# CH585SFR register map
Vendor: WCH Ltd.; Series: CH58x; File version: 1.0
CPU: RISC-V r0p0, little endian, no MPU, no FPU, 2 interrupt priority bits
Registers are 8-bit, Read or Write, reset 0x0 unless marked. A register's access mark holds for its fields unless they carry their own. Offsets are from the block's base; [hi:lo] are bit positions.

## TouchKey — Touch buttons
Base 0x40001000
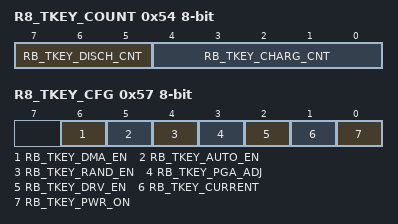
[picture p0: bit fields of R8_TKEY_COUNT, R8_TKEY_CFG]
0x54 R8_TKEY_COUNT reset not defined — RW, Touchkey charge and discharge count
  [7:5] RB_TKEY_DISCH_CNT — RW, Touchkey discharge count
  [4:0] RB_TKEY_CHARG_CNT — RW, Touchkey charge count
0x56 R8_TKEY_CONVERT — RW, Touchkey convert start control
  [0] RB_TKEY_START
0x57 R8_TKEY_CFG — RW, Touchkey configure
  [6] RB_TKEY_DMA_EN — RW, TouchKey DMA Enable
  [5] RB_TKEY_AUTO_EN — RW, TouchKey automatic trigger enable
  [4] RB_TKEY_RAND_EN — RW, TouchKey random trigger enable
  [3] RB_TKEY_PGA_ADJ — RW, ADC input PGA speed selection
  [2] RB_TKEY_DRV_EN — RW, Touchkey drive shield enable
  [1] RB_TKEY_CURRENT Read Only — R0, Touchkey charge current selection
  [0] RB_TKEY_PWR_ON — RW, Touchkey power on
0x7C R32_TKEY_SEL 32-bit — RW, TouchKey selection register
  [31:18] RB_TKEY_DRV_OUTEN — RW, TouchKey multi-channel driver shields each channel to enable

## ADC — Analog to Digital Converter
Base 0x40001000
0x58 R8_ADC_CHANNEL reset 0x10 — RW, ADC input channel selection
  [4:0] RB_ADC_CH_INX — RW, ADC input channel index
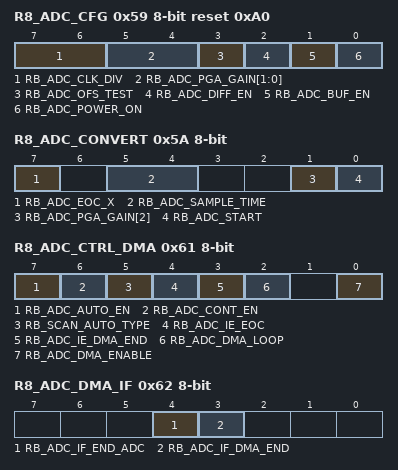
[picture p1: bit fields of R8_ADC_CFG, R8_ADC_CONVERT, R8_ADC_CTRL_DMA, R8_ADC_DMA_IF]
0x59 R8_ADC_CFG reset 0xA0 — RW, ADC configure
  [7:6] RB_ADC_CLK_DIV — RW, select ADC clock frequency: 00=3.2MHz, 01=2.67MHz, 10=5.33MHz, 11=4MHz
  [5:4] RB_ADC_PGA_GAIN[1:0] — RW, set ADC input PGA gain: 00=-12dB, 01=-6dB, 10=0dB, 11=6dB
  [3] RB_ADC_OFS_TEST — RW, enable ADC offset test mode: 0=normal mode, 1=short to test offset
  [2] RB_ADC_DIFF_EN — RW, ADC input channel mode: 0=single-end, 1=differnetial
  [1] RB_ADC_BUF_EN — RW, ADC input buffer enable
  [0] RB_ADC_POWER_ON — RW, ADC power control: 0=power down, 1=power on
0x5A R8_ADC_CONVERT — RW, ADC convert control
  [7] RB_ADC_EOC_X ro — RO, end of ADC conversion flag
  [5:4] RB_ADC_SAMPLE_TIME — RW, ADC sampling period selection
  [1] RB_ADC_PGA_GAIN[2] — RW, ADC input PGA gain direction selection, combined with RB_ ADC_ PGA_ GAIN [1:0] usage
  [0] RB_ADC_START — RW, ADC convert start control: 0=stop ADC convert, 1=start an ADC convert, auto clear
0x5B R8_TEM_SENSOR — RW, temperature sensor control
  [7] RB_TEM_SEN_PWR_ON — RW, temperature sensor power control: 0=power down, 1=power on
0x5C R16_ADC_DATA 16-bit ro reset not defined — RO, ADC data
  [11:0] RB_ADC_DATA — RO, ADC conversion data
0x5E R8_ADC_INT_FLAG ro — RO, ADC interrupt flag register
  [7] RB_ADC_IF_EOC — RO, ADC conversion interrupt flag
0x61 R8_ADC_CTRL_DMA write-read — RW, ADC DMA control
  [7] RB_ADC_AUTO_EN — RW, enable auto continuing ADC for DMA
  [6] RB_ADC_CONT_EN — RW, enable contineous conversion ADC
  [5] RB_SCAN_AUTO_TYPE — RW, ADC SCAN mode: 1: continuous triggering 0: periodic triggering
  [4] RB_ADC_IE_EOC — RW, enable interrupt for end of ADC conversion
  [3] RB_ADC_IE_DMA_END — RW, enable interrupt for ADC DMA completion
  [2] RB_ADC_DMA_LOOP — RW, ADC DMA address loop enable
  [0] RB_ADC_DMA_ENABLE — RW, ADC DMA enable
0x62 R8_ADC_DMA_IF write-read — RW1, ADC and DMA interrupt flag registers
  [4] RB_ADC_IF_END_ADC — interrupt flag for end of ADC conversion
  [3] RB_ADC_IF_DMA_END — interrupt flag for ADC DMA completion
0x63 R8_ADC_AUTO_CYCLE write-read reset not defined — RO, ADC interrupt flag
  [7:0] R8_ADC_AUTO_CYCLE — auto ADC cycle value, unit is 16 Fsys
0x64 R16_ADC_DMA_NOW ro reset not defined — RO, ADC DMA current address
  [16:1] R16_ADC_DMA_NOW — ADC DMA current address
0x68 R16_ADC_DMA_BEG write-read reset not defined — RW, ADC DMA begin address
  [16:1] R16_ADC_DMA_BEG — ADC DMA begin address
0x6C R16_ADC_DMA_END write-read reset not defined — RW, ADC DMA end address
  [16:1] R16_ADC_DMA_END — ADC DMA end address
